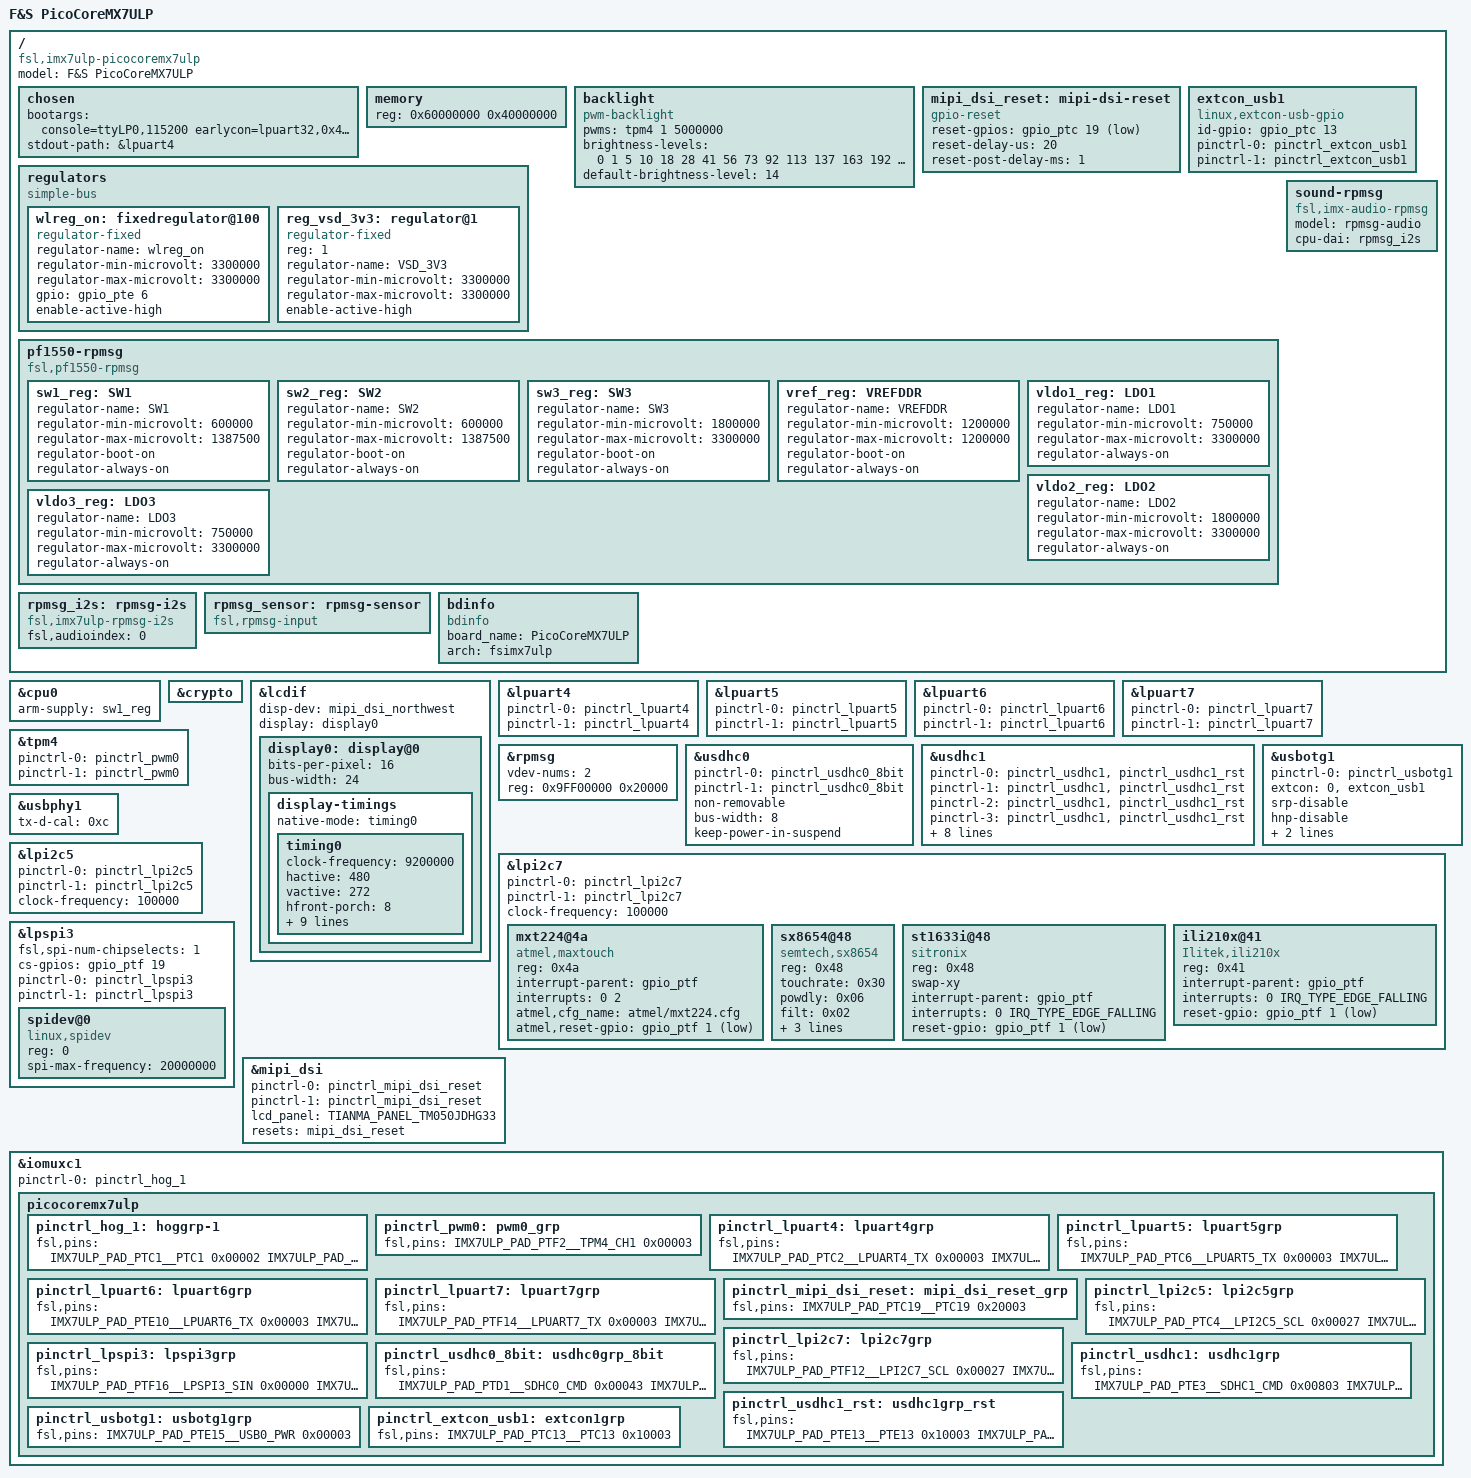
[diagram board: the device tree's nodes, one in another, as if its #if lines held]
/*
 * Copyright (C) 2016-2019 F&S Elektronik Systeme GmbH
 *
 * This program is free software; you can redistribute it and/or modify
 * it under the terms of the GNU General Public License version 2 as
 * published by the Free Software Foundation.
 */

/dts-v1/;

/* Set board revision as 3-digit number, e.g. 120 for board rev. 1.20 */
#define CONFIG_PICOCOREMX7ULP_BOARD_REVISION	120

/* GPIO numbers
 *
 * IOMUXC1 handles ports C - F
 * They are represented by GPIO0 - GPIO3
 * gpio0 == PTC
 * gpio1 == PTD
 * gpio2 == PTE
 * gpio3 == PTF
 */

#define DISPLAY_NONE		0	/* No display on this port */
#define DISPLAY_MIPI_DSI	1	/* MIPI_DSI display */

/*
 * Set the display configuration:
 *
 * - If you have no display, set LCDIF to DISPLAY_NONE.
 * - If you have a MIPI DSI display, set LCDIF to DISPLAY_MIPI_DSI.
 */
#define CONFIG_PICOCOREMX7ULP_LCDIF	DISPLAY_MIPI_DSI

/*
 * Configure touch screen:
 *
 * - 4-wire/5-wire analog resistive touch, touch controller on SKIT
 * - PCAP touch based on Maxtouch controller (MXT224, etc.), on Touch Connector
 * - PCAP touch based on Sitronix controller (ST1633i), on Touch Connector
 * - PCAP touch based on Ilitek controller (ILI12xx), on Touch Connector
 *
 * On picocoremx7ulp, all touches use the same interrupt line and I2C bus, so do not
 * select more than one entry! Select none if you do not need touch support.
 */
//#define CONFIG_PICOCOREMX7ULP_4WTOUCH_SX8655_ONBOARD
//#define CONFIG_PICOCOREMX7ULP_CAPTOUCH_MXT224
//#define CONFIG_PICOCOREMX7ULP_CAPTOUCH_SITRONIX
//#define CONFIG_PICOCOREMX7ULP_CAPTOUCH_ILITEK

/* WLAN */
#define CONFIG_PICOCOREMX7ULP_WLAN

/* SD card */
#define CONFIG_PICOCOREMX7ULP_SD
#define CONFIG_PICOCOREMX7ULP_SD_CD
#define CONFIG_PICOCOREMX7ULP_SD_WP

/* I2C */
#define CONFIG_PICOCOREMX7ULP_I2C_A
#define CONFIG_PICOCOREMX7ULP_I2C_B
#define CONFIG_PICOCOREMX7ULP_I2C_C

/* SPI_A */
#define CONFIG_PICOCOREMX7ULP_SPI_A

/* UART */
#define CONFIG_PICOCOREMX7ULP_UART_A
#define CONFIG_PICOCOREMX7ULP_UART_B
#define CONFIG_PICOCOREMX7ULP_UART_C
#define CONFIG_PICOCOREMX7ULP_UART_D

/* On-board EMMC */
#define CONFIG_PICOCOREMX7ULP_EMMC

/* Check for invalid CONFIG combinations */

/* WLAN and SD can't be used at the same time */
#ifdef CONFIG_PICOCOREMX7ULP_WLAN
#undef CONFIG_PICOCOREMX7ULP_SD
#undef CONFIG_PICOCOREMX7ULP_SD_CD
#undef CONFIG_PICOCOREMX7ULP_SD_WP
#endif

#include "imx7ulp.dtsi"
#include <dt-bindings/input/input.h>

/ {
	model = "F&S PicoCoreMX7ULP";
	compatible = "fsl,imx7ulp-picocoremx7ulp", "fsl,imx7ulp";

	chosen {
		bootargs = "console=ttyLP0,115200 earlycon=lpuart32,0x402D0000,115200";
		stdout-path = &lpuart4;
	};


	memory {
		device_type = "memory";
		reg = <0x60000000 0x40000000>;
	};

	backlight {
		compatible = "pwm-backlight";
		pwms = <&tpm4 1 5000000>;
		brightness-levels = <0 1 5 10 18 28 41 56
				     73 92 113 137 163 192 222 255>;
		default-brightness-level = <14>;
		status = "okay";
	};

#if (CONFIG_PICOCOREMX7ULP_LCDIF == DISPLAY_MIPI_DSI)
	mipi_dsi_reset: mipi-dsi-reset {
		compatible = "gpio-reset";
		/* ### TODO: no reset pin defined */
		reset-gpios = <&gpio_ptc 19 GPIO_ACTIVE_LOW>;
		reset-delay-us = <20>;
		reset-post-delay-ms =<1>;
		#reset-cells = <0>;
	};
#endif

	regulators {
		compatible = "simple-bus";
		#address-cells = <1>;
		#size-cells = <0>;

#ifdef CONFIG_PICOCOREMX7ULP_WLAN
		wlreg_on: fixedregulator@100 {
			compatible = "regulator-fixed";
			regulator-name = "wlreg_on";
			regulator-min-microvolt = <3300000>;
			regulator-max-microvolt = <3300000>;
			gpio = <&gpio_pte 6 GPIO_ACTIVE_HIGH>;
			enable-active-high;
		};
#endif

		reg_vsd_3v3: regulator@1 {
			compatible = "regulator-fixed";
			reg = <1>;
			regulator-name = "VSD_3V3";
			regulator-min-microvolt = <3300000>;
			regulator-max-microvolt = <3300000>;
			enable-active-high;
		};
	};

	extcon_usb1: extcon_usb1 {
		compatible = "linux,extcon-usb-gpio";
		id-gpio = <&gpio_ptc 13 GPIO_ACTIVE_HIGH>;
		pinctrl-names = "default", "sleep";
		pinctrl-0 = <&pinctrl_extcon_usb1>;
		pinctrl-1 = <&pinctrl_extcon_usb1>;
	};

	pf1550-rpmsg {
		compatible = "fsl,pf1550-rpmsg";
		sw1_reg: SW1 {
				regulator-name = "SW1";
				regulator-min-microvolt = <600000>;
				regulator-max-microvolt = <1387500>;
				regulator-boot-on;
				regulator-always-on;
		};

		sw2_reg: SW2 {
				regulator-name = "SW2";
				regulator-min-microvolt = <600000>;
				regulator-max-microvolt = <1387500>;
				regulator-boot-on;
				regulator-always-on;
		};

		sw3_reg: SW3 {
				regulator-name = "SW3";
				regulator-min-microvolt = <1800000>;
				regulator-max-microvolt = <3300000>;
				regulator-boot-on;
				regulator-always-on;
		};

		vref_reg: VREFDDR {
				regulator-name = "VREFDDR";
				regulator-min-microvolt = <1200000>;
				regulator-max-microvolt = <1200000>;
				regulator-boot-on;
				regulator-always-on;
		};

		vldo1_reg: LDO1 {
				regulator-name = "LDO1";
				regulator-min-microvolt = <750000>;
				regulator-max-microvolt = <3300000>;
				regulator-always-on;
		};

		vldo2_reg: LDO2 {
				regulator-name = "LDO2";
				regulator-min-microvolt = <1800000>;
				regulator-max-microvolt = <3300000>;
				regulator-always-on;
		};

		vldo3_reg: LDO3 {
				regulator-name = "LDO3";
				regulator-min-microvolt = <750000>;
				regulator-max-microvolt = <3300000>;
				regulator-always-on;
		};
	};

	rpmsg_i2s: rpmsg-i2s {
		compatible = "fsl,imx7ulp-rpmsg-i2s";
		/* the audio device index in m4 domain */
		fsl,audioindex = <0> ;
		status = "okay";
	};
	rpmsg_sensor: rpmsg-sensor {
		compatible = "fsl,rpmsg-input";
	};

	sound-rpmsg {
		compatible = "fsl,imx-audio-rpmsg";
		model = "rpmsg-audio";
		cpu-dai = <&rpmsg_i2s>;
	};

	/* F&S board information */
	bdinfo {
		compatible = "bdinfo";
		board_name = "PicoCoreMX7ULP";
		arch = "fsimx7ulp";
	};
};

&cpu0 {
	arm-supply= <&sw1_reg>;
};

/* kernel panic if its enabled - Job Ring error
 * error doesn´t occur if CONFIG_SOC_MX6Q is set.
 * In Kernel 4.14.98 it works without CONFIG_SOC_MX6Q.
 * Remove CONFIG_SOC_MX6Q if kernel version is >= 4.14.98
 */
&crypto {
	status = "okay";
};

#if (CONFIG_PICOCOREMX7ULP_LCDIF == DISPLAY_MIPI_DSI)
&lcdif {
	disp-dev = "mipi_dsi_northwest";
	display = <&display0>;
	status = "okay";
	/* This is a dummy definition for a display, needed by the mxsfb driver.
	   These values will get overwritten by the panel-specific values, defined in the
	   respective mipi driver file */
	display0: display@0 {
		bits-per-pixel = <16>;
		bus-width = <24>;
		display-timings {
			native-mode = <&timing0>;
			timing0: timing0 {
			clock-frequency = <9200000>;
			hactive = <480>;
			vactive = <272>;
			hfront-porch = <8>;
			hback-porch = <4>;
			hsync-len = <41>;
			vback-porch = <2>;
			vfront-porch = <4>;
			vsync-len = <10>;
			hsync-active = <0>;
			vsync-active = <0>;
			de-active = <1>;
			pixelclk-active = <0>;
			};
		};
	};
};
#endif

#ifdef CONFIG_PICOCOREMX7ULP_UART_A
&lpuart4 { /* console */
	pinctrl-names = "default", "sleep";
	pinctrl-0 = <&pinctrl_lpuart4>;
	pinctrl-1 = <&pinctrl_lpuart4>;
	status = "okay";
};
#endif

#ifdef CONFIG_PICOCOREMX7ULP_UART_B
&lpuart5 {
	pinctrl-names = "default", "sleep";
	pinctrl-0 = <&pinctrl_lpuart5>;
	pinctrl-1 = <&pinctrl_lpuart5>;
	status = "okay";
};
#endif

#ifdef CONFIG_PICOCOREMX7ULP_UART_C
&lpuart6 {
	pinctrl-names = "default", "sleep";
	pinctrl-0 = <&pinctrl_lpuart6>;
	pinctrl-1 = <&pinctrl_lpuart6>;
	status = "okay";
};
#endif

#ifdef CONFIG_PICOCOREMX7ULP_UART_D
&lpuart7 {
	pinctrl-names = "default", "sleep";
	pinctrl-0 = <&pinctrl_lpuart7>;
	pinctrl-1 = <&pinctrl_lpuart7>;
	status = "okay";
};
#endif

&tpm4 {
	pinctrl-names = "default", "sleep";
	pinctrl-0 = <&pinctrl_pwm0>;
	pinctrl-1 = <&pinctrl_pwm0>;
	status = "okay";
};

&rpmsg{
	/*
	 * 64K for one rpmsg instance, default using 2 rpmsg instances:
	 * --0x9FF00000~0x9FF0FFFF: pmic,pm,audio,keys,gpio,sensor
	 * --0x9FF10000~0x9FF1FFFF: pingpong,virtual tty
	 */
	vdev-nums = <2>;
	reg = <0x9FF00000 0x20000>;
	status = "okay";
};

#ifdef CONFIG_PICOCOREMX7ULP_EMMC
&usdhc0 { /* emmc */
	pinctrl-names = "default", "sleep";
	pinctrl-0 = <&pinctrl_usdhc0_8bit>;
	pinctrl-1 = <&pinctrl_usdhc0_8bit>;
	non-removable;
	bus-width = <8>;
	keep-power-in-suspend;
	status = "okay";
};
#endif

#if (defined(CONFIG_PICOCOREMX7ULP_SD) || defined(CONFIG_PICOCOREMX7ULP_WLAN))
&usdhc1 { /* sd card  or wlan */
	pinctrl-names = "default", "state_100mhz", "state_200mhz", "sleep";
	pinctrl-0 = <&pinctrl_usdhc1 &pinctrl_usdhc1_rst>;
	pinctrl-1 = <&pinctrl_usdhc1 &pinctrl_usdhc1_rst>;
	pinctrl-2 = <&pinctrl_usdhc1 &pinctrl_usdhc1_rst>;
	pinctrl-3 = <&pinctrl_usdhc1 &pinctrl_usdhc1_rst>;
	bus-width = <4>;
	vqmmc-supply = <&reg_vsd_3v3>;
#ifdef CONFIG_PICOCOREMX7ULP_WLAN
	vmmc-supply = <&wlreg_on>; /* VDD misused for RESET_WLAN/BT */
	non-removable;
	wifi-host; /* needed for BCM wifi cards */
	enable-sdio-wakeup;
#endif
#ifdef CONFIG_PICOCOREMX7ULP_SD_CD
	cd-gpios = <&gpio_pte 13 GPIO_ACTIVE_HIGH>;
	vmmc-supply = <&reg_vsd_3v3>;
#endif
	keep-power-in-suspend;
	status = "okay";
};
#endif

&usbotg1 {
	pinctrl-names = "default";
	pinctrl-0 = <&pinctrl_usbotg1>;
	/* Set ID Pin as extcon device instead of dedicated ID. There is
	 * a problem with resume mode if we are using dedicated ID function.
	 */
	extcon = <0>, <&extcon_usb1>;
	srp-disable;
	hnp-disable;
	adp-disable;
	disable-over-current;
	status = "okay";
};

&usbphy1 {
	tx-d-cal = <0xc>;
};

#ifdef CONFIG_PICOCOREMX7ULP_I2C_A
&lpi2c5 {
	#address-cells = <1>;
	#size-cells = <0>;
	pinctrl-names = "default", "sleep";
	pinctrl-0 = <&pinctrl_lpi2c5>;
	pinctrl-1 = <&pinctrl_lpi2c5>;
	clock-frequency = <100000>;
	status = "okay";
};
#endif

/* TODO check node */
#ifdef CONFIG_PICOCOREMX7ULP_I2C_B
&lpi2c7 {
	#address-cells = <1>;
	#size-cells = <0>;
	pinctrl-names = "default",  "sleep";
	pinctrl-0 = <&pinctrl_lpi2c7>;
	pinctrl-1 = <&pinctrl_lpi2c7>;
	clock-frequency = <100000>;
	status = "okay";

	//TODO: check if atmel firmware works
#ifdef CONFIG_PICOCOREMX7ULP_CAPTOUCH_MXT224
	mxt224@4a {
		compatible = "atmel,maxtouch";
		reg = <0x4a>;
		interrupt-parent = <&gpio_ptf>;
		interrupts = <0 2>;
		atmel,cfg_name = "atmel/mxt224.cfg";
		atmel,reset-gpio = <&gpio_ptf 1 GPIO_ACTIVE_LOW>;
	};
#endif

	/* Touch driver SX8654 */
#ifdef CONFIG_PICOCOREMX7ULP_4WTOUCH_SX8655_ONBOARD
	sx8654@48 {
		compatible = "semtech,sx8654";
		reg = <0x48>;
		touchrate = <0x30>;
		powdly = <0x06>;
		filt = <0x02>;
		setdly = <0x08>;
		pinctrl-names = "default";
		interrupt-parent = <&gpio_ptf>;
		interrupts = <0 IRQ_TYPE_EDGE_FALLING>;
	};
#endif

#ifdef CONFIG_PICOCOREMX7ULP_CAPTOUCH_SITRONIX
	/* Sitronix PCAP touch on Touch-Connector (I2C) */
	st1633i@48 {
		compatible = "sitronix";
		reg = <0x48>;
		swap-xy;
		interrupt-parent = <&gpio_ptf>;
		interrupts = <0 IRQ_TYPE_EDGE_FALLING>;
		reset-gpio = <&gpio_ptf 1 GPIO_ACTIVE_LOW>;
	};
#endif

#ifdef CONFIG_PICOCOREMX7ULP_CAPTOUCH_ILITEK
	/* Ilitek PCAP touch on Touch-Connector (I2C) */
	ili210x@41 {
		compatible = "Ilitek,ili210x";
		reg = <0x41>;
		interrupt-parent = <&gpio_ptf>;
		interrupts = <0 IRQ_TYPE_EDGE_FALLING>;
		reset-gpio = <&gpio_ptf 1 GPIO_ACTIVE_LOW>;
	};
#endif
};
#endif

#ifdef CONFIG_PICOCOREMX7ULP_SPI_A
&lpspi3 {
	fsl,spi-num-chipselects = <1>;
	cs-gpios = <&gpio_ptf 19 0>;
	#address-cells = <1>;
	#size-cells = <0>;
	pinctrl-names = "default", "sleep";
	pinctrl-0 = <&pinctrl_lpspi3>;
	pinctrl-1 = <&pinctrl_lpspi3>;
	status = "okay";

	spidev@0 {
		#address-cells = <1>;
		#size-cells = <1>;
		reg = <0>;
		compatible = "linux,spidev";
		spi-max-frequency = <20000000>;
	};
};
#endif

#if (CONFIG_PICOCOREMX7ULP_LCDIF == DISPLAY_MIPI_DSI)
&mipi_dsi {
	status = "okay";
	pinctrl-names = "default", "sleep";
	pinctrl-0 = <&pinctrl_mipi_dsi_reset>;
	pinctrl-1 = <&pinctrl_mipi_dsi_reset>;
	lcd_panel = "TIANMA_PANEL_TM050JDHG33";
	resets = <&mipi_dsi_reset>;
};
#endif

/* iomxuc pad settings PTC - PTF */
&iomuxc1 {
	pinctrl-names = "default";
	pinctrl-0 = <&pinctrl_hog_1>;

	picocoremx7ulp {
		pinctrl_hog_1: hoggrp-1 {
			fsl,pins = <
				/* TP 5 */
				IMX7ULP_PAD_PTC1__PTC1		0x00002

				/* GPIOs -> default low for A7 */
				/* 1.8V/3.3V PTE */
#ifndef CONFIG_PICOCOREMX7ULP_WLAN
				/* WL_PDn */
				IMX7ULP_PAD_PTE6__PTE6		0x00002
#endif
#ifndef CONFIG_PICOCOREMX7ULP_SD_CD
				IMX7ULP_PAD_PTE13__PTE13	0x00002
#endif
#ifndef CONFIG_PICOCOREMX7ULP_SD_WP
				IMX7ULP_PAD_PTE12__PTE12	0x00002
#endif
				/* BT_REG_ON */
				IMX7ULP_PAD_PTE7__PTE7		0x00002

				/* 1.8 V */
				IMX7ULP_PAD_PTC9__PTC9		0x00002
				IMX7ULP_PAD_PTC11__PTC11	0x00002
				IMX7ULP_PAD_PTC12__PTC12	0x00002
				IMX7ULP_PAD_PTC8__PTC8		0x00002
				IMX7ULP_PAD_PTC14__PTC14	0x00002
				IMX7ULP_PAD_PTC15__PTC15	0x00002
				IMX7ULP_PAD_PTC16__PTC16	0x00002
				IMX7ULP_PAD_PTC17__PTC17	0x00002
				IMX7ULP_PAD_PTC18__PTC18	0x00002

				/* 3.3 V */
				IMX7ULP_PAD_PTF3__PTF3		0x00002
				IMX7ULP_PAD_PTF4__PTF4		0x00002
				IMX7ULP_PAD_PTF5__PTF5		0x00002
				IMX7ULP_PAD_PTF6__PTF6		0x00002
				IMX7ULP_PAD_PTF7__PTF7		0x00002
				IMX7ULP_PAD_PTF8__PTF8		0x00002
				IMX7ULP_PAD_PTF9__PTF9		0x00002
				IMX7ULP_PAD_PTF10__PTF10	0x00002
				IMX7ULP_PAD_PTF11__PTF11	0x00002

				/* I2C7n IRQ */
				IMX7ULP_PAD_PTF0__PTF0		0x10003

				/* I2C7n RST */
				IMX7ULP_PAD_PTF1__PTF1		0x20003

#if (CONFIG_PICOCOREMX7ULP_LCDIF == MIPI_DSI)
				/* TC358762 RST */
				IMX7ULP_PAD_PTC19__PTC19	0x20002
#endif

				/* USHC1_VSEL */
			//	IMX7ULP_PAD_PTE14__SDHC1_VS	0x43
			>;
		};

		pinctrl_pwm0: pwm0_grp {
			fsl,pins = <
				IMX7ULP_PAD_PTF2__TPM4_CH1	0x00003
			>;
		};

#ifdef CONFIG_PICOCOREMX7ULP_UART_A
		pinctrl_lpuart4: lpuart4grp {
			fsl,pins = <
				IMX7ULP_PAD_PTC2__LPUART4_TX	0x00003
				IMX7ULP_PAD_PTC3__LPUART4_RX	0x00003
			>;
		};
#endif

#ifdef CONFIG_PICOCOREMX7ULP_UART_B
		pinctrl_lpuart5: lpuart5grp {
			fsl,pins = <
				IMX7ULP_PAD_PTC6__LPUART5_TX	0x00003
				IMX7ULP_PAD_PTC7__LPUART5_RX	0x00003
			>;
		};
#endif

#ifdef CONFIG_PICOCOREMX7ULP_UART_C
		pinctrl_lpuart6: lpuart6grp {
			fsl,pins = <
				IMX7ULP_PAD_PTE10__LPUART6_TX	0x00003
				IMX7ULP_PAD_PTE11__LPUART6_RX	0x00003
				IMX7ULP_PAD_PTE8__LPUART6_CTS_B	0x00003
				IMX7ULP_PAD_PTE9__LPUART6_RTS_B	0x00003
			>;
		};
#endif

#ifdef CONFIG_PICOCOREMX7ULP_UART_D
		pinctrl_lpuart7: lpuart7grp {
			fsl,pins = <
				IMX7ULP_PAD_PTF14__LPUART7_TX	0x00003
 				IMX7ULP_PAD_PTF15__LPUART7_RX	0x00003
			>;
		};
#endif

#if (CONFIG_PICOCOREMX7ULP_LCDIF == DISPLAY_MIPI_DSI)
		pinctrl_mipi_dsi_reset: mipi_dsi_reset_grp {
			fsl,pins = <
				IMX7ULP_PAD_PTC19__PTC19	0x20003
			>;
		};
#endif

#ifdef CONFIG_PICOCOREMX7ULP_I2C_A
		pinctrl_lpi2c5: lpi2c5grp {
			fsl,pins = <
				IMX7ULP_PAD_PTC4__LPI2C5_SCL	0x00027
				IMX7ULP_PAD_PTC5__LPI2C5_SDA	0x00027
			>;
		};
#endif

#ifdef CONFIG_PICOCOREMX7ULP_I2C_B
		pinctrl_lpi2c7: lpi2c7grp {
			fsl,pins = <
				IMX7ULP_PAD_PTF12__LPI2C7_SCL	0x00027
				IMX7ULP_PAD_PTF13__LPI2C7_SDA	0x00027
			>;
		};
#endif

#ifdef CONFIG_PICOCOREMX7ULP_SPI_A
		pinctrl_lpspi3: lpspi3grp {
			fsl,pins = <
				IMX7ULP_PAD_PTF16__LPSPI3_SIN	0x00000
				IMX7ULP_PAD_PTF17__LPSPI3_SOUT	0x00000
				IMX7ULP_PAD_PTF18__LPSPI3_SCK	0x00000
				IMX7ULP_PAD_PTF19__LPSPI3_PCS0	0x00000
			>;
		};
#endif

#ifdef CONFIG_PICOCOREMX7ULP_EMMC
		pinctrl_usdhc0_8bit: usdhc0grp_8bit {
			fsl,pins = <
				IMX7ULP_PAD_PTD1__SDHC0_CMD	0x00043
				IMX7ULP_PAD_PTD2__SDHC0_CLK	0x00043
				IMX7ULP_PAD_PTD3__SDHC0_D7	0x00043
				IMX7ULP_PAD_PTD4__SDHC0_D6	0x00043
				IMX7ULP_PAD_PTD5__SDHC0_D5	0x00043
				IMX7ULP_PAD_PTD6__SDHC0_D4	0x00043
				IMX7ULP_PAD_PTD7__SDHC0_D3	0x00043
				IMX7ULP_PAD_PTD8__SDHC0_D2	0x00043
				IMX7ULP_PAD_PTD9__SDHC0_D1	0x00043
				IMX7ULP_PAD_PTD10__SDHC0_D0	0x00043
				/* CD pin - n.c. */
				IMX7ULP_PAD_PTC10__PTC10	0x10002
				/* nRST */
				IMX7ULP_PAD_PTD0__PTD0		0x00003
			>;
		};
#endif

#if (defined(CONFIG_PICOCOREMX7ULP_SD) || defined(CONFIG_PICOCOREMX7ULP_WLAN))
		pinctrl_usdhc1: usdhc1grp {
			fsl,pins = <
				IMX7ULP_PAD_PTE3__SDHC1_CMD	0x00803
				IMX7ULP_PAD_PTE2__SDHC1_CLK	0x00800
				IMX7ULP_PAD_PTE1__SDHC1_D0	0x00803
				IMX7ULP_PAD_PTE0__SDHC1_D1	0x00803
				IMX7ULP_PAD_PTE5__SDHC1_D2	0x00803
				IMX7ULP_PAD_PTE4__SDHC1_D3	0x00803
			>;
		};

		pinctrl_usdhc1_rst: usdhc1grp_rst {
			fsl,pins = <
#ifdef CONFIG_PICOCOREMX7ULP_SD_CD
				/* USDHC1 card detect */
				IMX7ULP_PAD_PTE13__PTE13	0x10003
#endif
#ifdef CONFIG_PICOCOREMX7ULP_SD_WP
				/* USDHC1 WP */
				IMX7ULP_PAD_PTE12__PTE12	0x10003
#endif
#ifdef CONFIG_PICOCOREMX7ULP_WLAN
				/* WL_PDn */
				IMX7ULP_PAD_PTE6__PTE6		0x10003
#endif
			>;
		};
#endif

		pinctrl_usbotg1: usbotg1grp {
			fsl,pins = <
				/* USB otg Power enable */
				IMX7ULP_PAD_PTE15__USB0_PWR	0x00003
			>;
		};

		pinctrl_extcon_usb1: extcon1grp {
			fsl,pins = <
				IMX7ULP_PAD_PTC13__PTC13	0x10003
			>;
		};
	};
};
